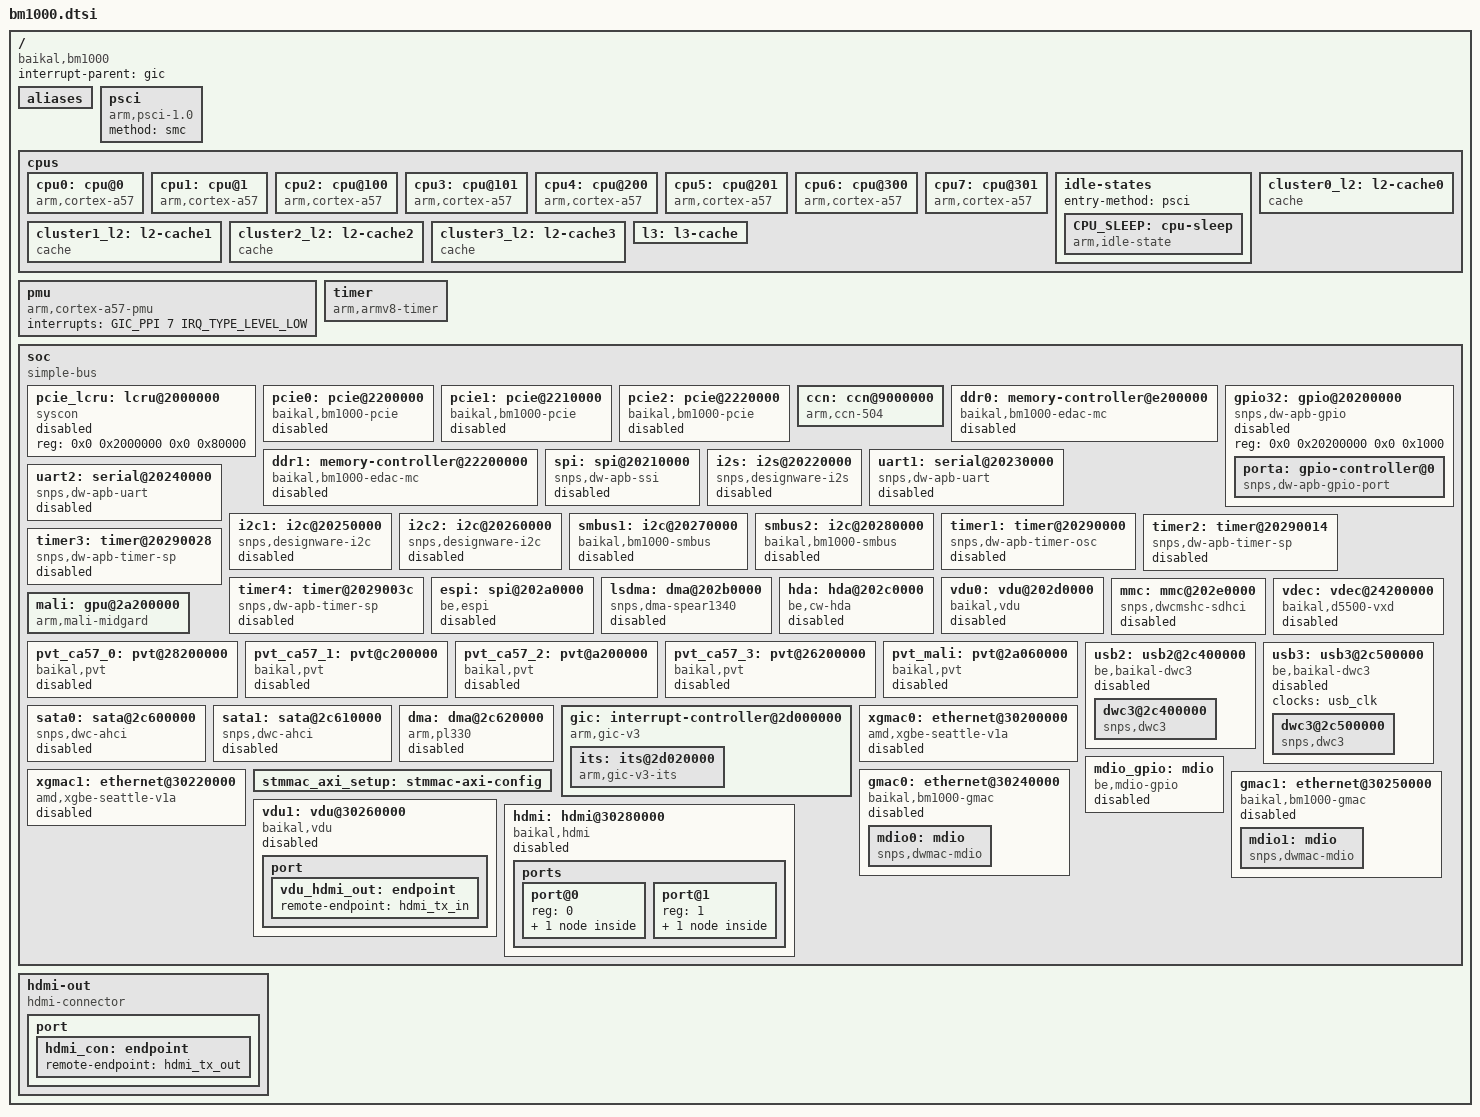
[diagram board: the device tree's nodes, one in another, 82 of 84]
// SPDX-License-Identifier: GPL-2.0
/*
 * Device tree include file for BE-M1000 SoC
 * Copyright (C) 2017-2021 Baikal Electronics, JSC
 */

#include "bm1000-clocks.dtsi"
#include <dt-bindings/gpio/gpio.h>
#include <dt-bindings/interrupt-controller/arm-gic.h>

/ {
	compatible = "baikal,bm1000";
	#address-cells = <2>;
	#size-cells = <2>;
	interrupt-parent = <&gic>;

	aliases {
		i2c1	= &i2c1;
		i2c2	= &i2c2;
		i2c3	= &smbus1;
		i2c4	= &smbus2;
		serial0	= &uart1;
		serial1	= &uart2;
	};

	psci {
		compatible = "arm,psci-1.0", "arm,psci-0.2";
		method = "smc";
	};

	cpus {
		#address-cells = <2>;
		#size-cells = <0>;

		/* Do not use 'cpu-map'. It leads to wrong topology. */

		cpu0: cpu@0 {
			device_type = "cpu";
			compatible = "arm,cortex-a57";
			reg = <0x0 0x0>;
			enable-method = "psci";
			i-cache-size = <0xc000>;
			i-cache-line-size = <64>;
			i-cache-sets = <256>;
			d-cache-size = <0x8000>;
			d-cache-line-size = <64>;
			d-cache-sets = <256>;
			next-level-cache = <&cluster0_l2>;
			clocks = <&cmu_cluster0>;
			clock-names = "baikal-ca57_cmu";
			operating-points-v2 = <&cluster0_opp>;
			cpu-idle-states = <&CPU_SLEEP>;
		};

		cpu1: cpu@1 {
			device_type = "cpu";
			compatible = "arm,cortex-a57";
			reg = <0x0 0x1>;
			enable-method = "psci";
			i-cache-size = <0xc000>;
			i-cache-line-size = <64>;
			i-cache-sets = <256>;
			d-cache-size = <0x8000>;
			d-cache-line-size = <64>;
			d-cache-sets = <256>;
			next-level-cache = <&cluster0_l2>;
			clocks = <&cmu_cluster0>;
			clock-names = "baikal-ca57_cmu";
			operating-points-v2 = <&cluster0_opp>;
			cpu-idle-states = <&CPU_SLEEP>;
		};

		cpu2: cpu@100 {
			device_type = "cpu";
			compatible = "arm,cortex-a57";
			reg = <0x0 0x100>;
			enable-method = "psci";
			i-cache-size = <0xc000>;
			i-cache-line-size = <64>;
			i-cache-sets = <256>;
			d-cache-size = <0x8000>;
			d-cache-line-size = <64>;
			d-cache-sets = <256>;
			next-level-cache = <&cluster1_l2>;
			clocks = <&cmu_cluster1>;
			clock-names = "baikal-ca57_cmu";
			operating-points-v2 = <&cluster1_opp>;
			cpu-idle-states = <&CPU_SLEEP>;
		};

		cpu3: cpu@101 {
			device_type = "cpu";
			compatible = "arm,cortex-a57";
			reg = <0x0 0x101>;
			enable-method = "psci";
			i-cache-size = <0xc000>;
			i-cache-line-size = <64>;
			i-cache-sets = <256>;
			d-cache-size = <0x8000>;
			d-cache-line-size = <64>;
			d-cache-sets = <256>;
			next-level-cache = <&cluster1_l2>;
			clocks = <&cmu_cluster1>;
			clock-names = "baikal-ca57_cmu";
			operating-points-v2 = <&cluster1_opp>;
			cpu-idle-states = <&CPU_SLEEP>;
		};

		cpu4: cpu@200 {
			device_type = "cpu";
			compatible = "arm,cortex-a57";
			reg = <0x0 0x200>;
			enable-method = "psci";
			i-cache-size = <0xc000>;
			i-cache-line-size = <64>;
			i-cache-sets = <256>;
			d-cache-size = <0x8000>;
			d-cache-line-size = <64>;
			d-cache-sets = <256>;
			next-level-cache = <&cluster2_l2>;
			clocks = <&cmu_cluster2>;
			clock-names = "baikal-ca57_cmu";
			operating-points-v2 = <&cluster2_opp>;
			cpu-idle-states = <&CPU_SLEEP>;
		};

		cpu5: cpu@201 {
			device_type = "cpu";
			compatible = "arm,cortex-a57";
			reg = <0x0 0x201>;
			enable-method = "psci";
			i-cache-size = <0xc000>;
			i-cache-line-size = <64>;
			i-cache-sets = <256>;
			d-cache-size = <0x8000>;
			d-cache-line-size = <64>;
			d-cache-sets = <256>;
			next-level-cache = <&cluster2_l2>;
			clocks = <&cmu_cluster2>;
			clock-names = "baikal-ca57_cmu";
			operating-points-v2 = <&cluster2_opp>;
			cpu-idle-states = <&CPU_SLEEP>;
		};

		cpu6: cpu@300 {
			device_type = "cpu";
			compatible = "arm,cortex-a57";
			reg = <0x0 0x300>;
			enable-method = "psci";
			i-cache-size = <0xc000>;
			i-cache-line-size = <64>;
			i-cache-sets = <256>;
			d-cache-size = <0x8000>;
			d-cache-line-size = <64>;
			d-cache-sets = <256>;
			next-level-cache = <&cluster3_l2>;
			clocks = <&cmu_cluster3>;
			clock-names = "baikal-ca57_cmu";
			operating-points-v2 = <&cluster3_opp>;
			cpu-idle-states = <&CPU_SLEEP>;
		};

		cpu7: cpu@301 {
			device_type = "cpu";
			compatible = "arm,cortex-a57";
			reg = <0x0 0x301>;
			enable-method = "psci";
			i-cache-size = <0xc000>;
			i-cache-line-size = <64>;
			i-cache-sets = <256>;
			d-cache-size = <0x8000>;
			d-cache-line-size = <64>;
			d-cache-sets = <256>;
			next-level-cache = <&cluster3_l2>;
			clocks = <&cmu_cluster3>;
			clock-names = "baikal-ca57_cmu";
			operating-points-v2 = <&cluster3_opp>;
			cpu-idle-states = <&CPU_SLEEP>;
		};

		idle-states {
			entry-method = "psci";

			CPU_SLEEP: cpu-sleep {
				compatible = "arm,idle-state";
				local-timer-stop;
				arm,psci-suspend-param = <0x0000001>;
				entry-latency-us = <300>;
				exit-latency-us = <1200>;
				min-residency-us = <2000>;
			};
		};

		cluster0_l2: l2-cache0 {
			compatible = "cache";
			cache-size = <0x100000>;
			cache-line-size = <64>;
			cache-sets = <1024>;
			cache-unified;
			cache-level = <2>;
			next-level-cache = <&l3>;
		};

		cluster1_l2: l2-cache1 {
			compatible = "cache";
			cache-size = <0x100000>;
			cache-line-size = <64>;
			cache-sets = <1024>;
			cache-unified;
			cache-level = <2>;
			next-level-cache = <&l3>;
		};

		cluster2_l2: l2-cache2 {
			compatible = "cache";
			cache-size = <0x100000>;
			cache-line-size = <64>;
			cache-sets = <1024>;
			cache-unified;
			cache-level = <2>;
			next-level-cache = <&l3>;
		};

		cluster3_l2: l2-cache3 {
			compatible = "cache";
			cache-size = <0x100000>;
			cache-line-size = <64>;
			cache-sets = <1024>;
			cache-unified;
			cache-level = <2>;
			next-level-cache = <&l3>;
		};

		l3: l3-cache {
			cache-size = <0x800000>;
			cache-unified;
			cache-level = <3>;
		};
	};

	pmu {
		compatible = "arm,cortex-a57-pmu";
		interrupts = <GIC_PPI 7 IRQ_TYPE_LEVEL_LOW>;
	};

	timer {
		compatible = "arm,armv8-timer";
		interrupts = <GIC_PPI 13 IRQ_TYPE_LEVEL_LOW>,
			     <GIC_PPI 14 IRQ_TYPE_LEVEL_LOW>,
			     <GIC_PPI 11 IRQ_TYPE_LEVEL_LOW>,
			     <GIC_PPI 10 IRQ_TYPE_LEVEL_LOW>;
	};

	soc {
		compatible = "simple-bus";
		#address-cells = <2>;
		#size-cells = <2>;
		ranges;

		pcie_lcru: lcru@2000000 {
			compatible = "syscon";
			reg = <0x0 0x2000000 0x0 0x80000>;
			status = "disabled";
		};

		pcie0: pcie@2200000 { /* PCIe x4 #0 */
			compatible = "baikal,bm1000-pcie", "baikal,pcie-m", "snps,dw-pcie";
			reg = <0x0 0x02200000 0x0 0x1000>,   /* RC config space */
			      <0x0 0x40100000 0x0 0x100000>; /* PCI config space */
			reg-names = "dbi", "config";
			interrupts = <GIC_SPI 426 IRQ_TYPE_LEVEL_HIGH>, /* AER */
				     <GIC_SPI 429 IRQ_TYPE_LEVEL_HIGH>; /* MSI */
			#interrupt-cells = <1>;
			baikal,pcie-lcru = <&pcie_lcru 0>;
			#address-cells = <3>;
			#size-cells = <2>;
			device_type = "pci";
			ranges = <0x81000000 0x0 0x00000000 0x0 0x40200000 0x0 0x100000>,   /* I/O */
				 <0x82000000 0x0 0x40000000 0x4 0x00000000 0x0 0x40000000>; /* 32b non-prefetchable memory */
			msi-parent = <&its 0x0>;
			msi-map = <0x0 &its 0x0 0x10000>;
			num-lanes = <4>;
			num-viewport = <4>;
			bus-range = <0x0 0xff>;
			status = "disabled";
		};

		pcie1: pcie@2210000 { /* PCIe x4 #1 */
			compatible = "baikal,bm1000-pcie", "baikal,pcie-m", "snps,dw-pcie";
			reg = <0x0 0x02210000 0x0 0x1000>,   /* RC config space */
			      <0x0 0x50100000 0x0 0x100000>; /* PCI config space */
			reg-names = "dbi", "config";
			interrupts = <GIC_SPI 402 IRQ_TYPE_LEVEL_HIGH>,	/* AER */
				     <GIC_SPI 405 IRQ_TYPE_LEVEL_HIGH>;	/* MSI */
			#interrupt-cells = <1>;
			baikal,pcie-lcru = <&pcie_lcru 1>;
			#address-cells = <3>;
			#size-cells = <2>;
			device_type = "pci";
			ranges = <0x81000000 0x0 0x00100000 0x0 0x50000000 0x0 0x100000>,   /* I/O */
				 <0x82000000 0x0 0x40000000 0x5 0x00000000 0x0 0x40000000>; /* 32b non-prefetchable memory */
			msi-parent = <&its 0x0>;
			msi-map = <0x0 &its 0x0 0x10000>;
			num-lanes = <4>;
			num-viewport = <4>;
			bus-range = <0x0 0xff>;
			status = "disabled";
		};

		pcie2: pcie@2220000 { /* PCIe x8 */
			compatible = "baikal,bm1000-pcie", "baikal,pcie-m", "snps,dw-pcie";
			reg = <0x0 0x02220000 0x0 0x1000>,   /* RC config space */
			      <0x0 0x60000000 0x0 0x100000>; /* PCI config space */
			reg-names = "dbi", "config";
			interrupts = <GIC_SPI 378 IRQ_TYPE_LEVEL_HIGH>, /* AER */
				     <GIC_SPI 381 IRQ_TYPE_LEVEL_HIGH>; /* MSI */
			#interrupt-cells = <1>;
			baikal,pcie-lcru = <&pcie_lcru 2>;
			#address-cells = <3>;
			#size-cells = <2>;
			device_type = "pci";
			ranges = <0x81000000 0x0 0x00200000 0x0 0x60100000 0x0 0x100000>,   /* I/O */
				 <0x82000000 0x0 0x80000000 0x6 0x00000000 0x0 0x80000000>; /* 32b non-prefetchable memory */
			msi-parent = <&its 0x0>;
			msi-map = <0x0 &its 0x0 0x10000>;
			num-lanes = <8>;
			num-viewport = <4>;
			bus-range = <0x0 0xff>;
			status = "disabled";
		};

		ccn: ccn@9000000 {
			compatible = "arm,ccn-504";
			reg = <0x0 0x9000000 0 0x1000000>;
			interrupts = <GIC_SPI 127 IRQ_TYPE_LEVEL_HIGH>;
		};

		ddr0: memory-controller@e200000 {
			compatible = "baikal,bm1000-edac-mc";
			reg = <0x0 0x0e200000 0x0 0x10000>;
			interrupts = <GIC_SPI 129 IRQ_TYPE_LEVEL_HIGH>, /* dfi_alert_err */
				     <GIC_SPI 130 IRQ_TYPE_LEVEL_HIGH>, /* ecc_corrected_err */
				     <GIC_SPI 131 IRQ_TYPE_LEVEL_HIGH>, /* ecc_uncorrected_err */
				     <GIC_SPI 132 IRQ_TYPE_LEVEL_HIGH>, /* sbr_done */
				     <GIC_SPI 133 IRQ_TYPE_LEVEL_HIGH>, /* ecc_corrected_err_fault */
				     <GIC_SPI 134 IRQ_TYPE_LEVEL_HIGH>; /* ecc_uncorrected_err_fault */
			clocks = <&soc_smc50mhz>;
			clock-names = "apb_pclk";
			status = "disabled";
		};

		ddr1: memory-controller@22200000 {
			compatible = "baikal,bm1000-edac-mc";
			reg = <0x0 0x22200000 0x0 0x10000>;
			interrupts = <GIC_SPI 139 IRQ_TYPE_LEVEL_HIGH>, /* dfi_alert_err */
				     <GIC_SPI 140 IRQ_TYPE_LEVEL_HIGH>, /* ecc_corrected_err */
				     <GIC_SPI 141 IRQ_TYPE_LEVEL_HIGH>, /* ecc_uncorrected_err */
				     <GIC_SPI 142 IRQ_TYPE_LEVEL_HIGH>, /* sbr_done */
				     <GIC_SPI 143 IRQ_TYPE_LEVEL_HIGH>, /* ecc_corrected_err_fault */
				     <GIC_SPI 144 IRQ_TYPE_LEVEL_HIGH>; /* ecc_uncorrected_err_fault */
			clocks = <&soc_smc50mhz>;
			clock-names = "apb_pclk";
			status = "disabled";
		};

		gpio32: gpio@20200000 {
			compatible = "snps,dw-apb-gpio";
			reg = <0x0 0x20200000 0x0 0x1000>;
			#address-cells = <1>;
			#size-cells = <0>;
			status = "disabled";

			porta: gpio-controller@0 {
				compatible = "snps,dw-apb-gpio-port";
				gpio-controller;
				#gpio-cells = <2>;
				snps,nr-gpios = <32>;
				reg = <0>;
				interrupt-controller;
				#interrupt-cells = <2>;
				interrupts = <GIC_SPI 99 IRQ_TYPE_LEVEL_HIGH>;
			};
		};

		spi: spi@20210000 {
			compatible = "snps,dw-apb-ssi";
			reg = <0x0 0x20210000 0x0 0x1000>;
			#address-cells = <1>;
			#size-cells = <0>;
			interrupts = <GIC_SPI 100 IRQ_TYPE_LEVEL_HIGH>;
			clocks = <&cmu0_avlsp 4>;
			clock-names = "soc_spiclk";
			status = "disabled";
		};

		i2s: i2s@20220000 {
			compatible = "snps,designware-i2s";
			reg = <0x0 0x20220000 0x0 0x10000>;
			interrupts = <GIC_SPI 104 IRQ_TYPE_LEVEL_HIGH>, /* rx_da */
				     <GIC_SPI 105 IRQ_TYPE_LEVEL_HIGH>, /* rx_or */
				     <GIC_SPI 106 IRQ_TYPE_LEVEL_HIGH>, /* tx_emp */
				     <GIC_SPI 107 IRQ_TYPE_LEVEL_HIGH>; /* tx_or */
			/*dmas = <&lsdma 0 1 0>,*/
			/*       <&lsdma 1 0 1>;*/
			/*dma-names = "tx", "rx";*/
			/*#sound-dai-cells = <0>;*/
			clocks = <&soc_tmp_clk>;
			clock-names = "i2sclk";
			status = "disabled";
		};

		uart1: serial@20230000 {
			compatible = "snps,dw-apb-uart";
			reg = <0x0 0x20230000 0x0 0x100>;
			interrupts = <GIC_SPI 101 IRQ_TYPE_LEVEL_HIGH>;
			reg-shift = <2>;
			reg-io-width = <4>;
			clocks = <&cmu0_avlsp 1>, <&apb_clk>;
			clock-names = "soc_uartclk", "apb_pclk";
			status = "disabled";
		};

		uart2: serial@20240000 {
			compatible = "snps,dw-apb-uart";
			reg = <0x0 0x20240000 0x0 0x100>;
			interrupts = <GIC_SPI 102 IRQ_TYPE_LEVEL_HIGH>;
			reg-shift = <2>;
			reg-io-width = <4>;
			clocks = <&cmu0_avlsp 2>, <&apb_clk>;
			clock-names = "soc_uartclk", "apb_pclk";
			status = "disabled";
		};

		i2c1: i2c@20250000 {
			compatible = "snps,designware-i2c";
			#address-cells = <1>;
			#size-cells = <0>;
			reg = <0x0 0x20250000 0x0 0x1000>;
			interrupts = <GIC_SPI 108 IRQ_TYPE_LEVEL_HIGH>;
			i2c-sda-hold-time-ns = <500>;
			clock-frequency = <400000>;
			clocks = <&i2c_clk>;
			clock-names = "soc_i2cclk";
			status = "disabled";
		};

		i2c2: i2c@20260000 {
			compatible = "snps,designware-i2c";
			#address-cells = <1>;
			#size-cells = <0>;
			reg = <0x0 0x20260000 0x0 0x1000>;
			interrupts = <GIC_SPI 109 IRQ_TYPE_LEVEL_HIGH>;
			i2c-sda-hold-time-ns = <500>;
			clock-frequency = <400000>;
			clocks = <&i2c_clk>;
			clock-names = "soc_i2cclk";
			status = "disabled";
		};

		smbus1: i2c@20270000 {
			compatible = "baikal,bm1000-smbus", "be,smbus";
			#address-cells = <1>;
			#size-cells = <0>;
			reg = <0x0 0x20270000 0x0 0x1000>;
			interrupts = <GIC_SPI 110 IRQ_TYPE_LEVEL_HIGH>;
			clock-frequency = <100000>;
			clocks = <&smbus_clk>;
			clock-names = "soc_smbusclk";
			status = "disabled";
		};

		smbus2: i2c@20280000 {
			compatible = "baikal,bm1000-smbus", "be,smbus";
			#address-cells = <1>;
			#size-cells = <0>;
			reg = <0x0 0x20280000 0x0 0x1000>;
			interrupts = <GIC_SPI 111 IRQ_TYPE_LEVEL_HIGH>;
			clock-frequency = <100000>;
			clocks = <&smbus_clk>;
			clock-names = "soc_smbusclk";
			status = "disabled";
		};

		timer1: timer@20290000 {
			compatible = "snps,dw-apb-timer-osc";
			reg = <0x0 0x20290000 0x0 0x14>;
			interrupts = <GIC_SPI 95 IRQ_TYPE_LEVEL_HIGH>;
			clock-frequency = <50000000>;
			clocks = <&timer1_clk>;
			clock-names = "soc_timer1clk";
			status = "disabled";
		};

		timer2: timer@20290014 {
			compatible = "snps,dw-apb-timer-sp";
			reg = <0x0 0x20290014 0x0 0x14>;
			interrupts = <GIC_SPI 96 IRQ_TYPE_LEVEL_HIGH>;
			clock-frequency = <50000000>;
			clocks = <&timer2_clk>;
			clock-names = "soc_timer2clk";
			status = "disabled";
		};

		timer3: timer@20290028 {
			compatible = "snps,dw-apb-timer-sp";
			reg = <0x0 0x20290028 0x0 0x14>;
			interrupts = <GIC_SPI 97 IRQ_TYPE_LEVEL_HIGH>;
			clock-frequency = <50000000>;
			clocks = <&timer3_clk>;
			clock-names = "soc_timer3clk";
			status = "disabled";
		};

		timer4: timer@2029003c {
			compatible = "snps,dw-apb-timer-sp";
			reg = <0x0 0x2029003c 0x0 0x14>;
			interrupts = <GIC_SPI 98 IRQ_TYPE_LEVEL_HIGH>;
			clock-frequency = <50000000>;
			clocks = <&timer4_clk>;
			clock-names = "soc_timer4clk";
			status = "disabled";
		};

		espi: spi@202a0000 {
			compatible = "be,espi";
			reg = <0x0 0x202a0000 0x0 0x1000>;
			#address-cells = <1>;
			#size-cells = <0>;
			interrupts = <GIC_SPI 103 IRQ_TYPE_LEVEL_HIGH>;
			clocks = <&cmu0_avlsp 5>;
			clock-names = "soc_espiclk";
			status = "disabled";
			/*
			 * Block Configuration:
			 * - master/slave
			 * - 32-bit APB slave
			 * - tx-fifo = rx-fifo = 256 byte
			 * - 4 SPI IO channels
			 * - 8 slave select IO channels
			 * - DMA - missing
			 * - M-flash controller - missing
			 */
		};

		lsdma: dma@202b0000 {
			compatible = "snps,dma-spear1340";
			reg = <0x0 0x202b0000 0x0 0x10000>;
			interrupts = <GIC_SPI 9 IRQ_TYPE_LEVEL_HIGH>,
				     <GIC_SPI 10 IRQ_TYPE_LEVEL_HIGH>,
				     <GIC_SPI 11 IRQ_TYPE_LEVEL_HIGH>,
				     <GIC_SPI 12 IRQ_TYPE_LEVEL_HIGH>,
				     <GIC_SPI 13 IRQ_TYPE_LEVEL_HIGH>,
				     <GIC_SPI 14 IRQ_TYPE_LEVEL_HIGH>,
				     <GIC_SPI 15 IRQ_TYPE_LEVEL_HIGH>,
				     <GIC_SPI 16 IRQ_TYPE_LEVEL_HIGH>,
				     <GIC_SPI 17 IRQ_TYPE_LEVEL_HIGH>,
				     <GIC_SPI 18 IRQ_TYPE_LEVEL_HIGH>,
				     <GIC_SPI 19 IRQ_TYPE_LEVEL_HIGH>,
				     <GIC_SPI 20 IRQ_TYPE_LEVEL_HIGH>,
				     <GIC_SPI 21 IRQ_TYPE_LEVEL_HIGH>,
				     <GIC_SPI 22 IRQ_TYPE_LEVEL_HIGH>,
				     <GIC_SPI 23 IRQ_TYPE_LEVEL_HIGH>,
				     <GIC_SPI 24 IRQ_TYPE_LEVEL_HIGH>,
				     <GIC_SPI 25 IRQ_TYPE_LEVEL_HIGH>,
				     <GIC_SPI 26 IRQ_TYPE_LEVEL_HIGH>,
				     <GIC_SPI 27 IRQ_TYPE_LEVEL_HIGH>,
				     <GIC_SPI 28 IRQ_TYPE_LEVEL_HIGH>,
				     <GIC_SPI 29 IRQ_TYPE_LEVEL_HIGH>,
				     <GIC_SPI 30 IRQ_TYPE_LEVEL_HIGH>,
				     <GIC_SPI 31 IRQ_TYPE_LEVEL_HIGH>,
				     <GIC_SPI 32 IRQ_TYPE_LEVEL_HIGH>,
				     <GIC_SPI 33 IRQ_TYPE_LEVEL_HIGH>,
				     <GIC_SPI 34 IRQ_TYPE_LEVEL_HIGH>,
				     <GIC_SPI 35 IRQ_TYPE_LEVEL_HIGH>,
				     <GIC_SPI 36 IRQ_TYPE_LEVEL_HIGH>,
				     <GIC_SPI 37 IRQ_TYPE_LEVEL_HIGH>,
				     <GIC_SPI 38 IRQ_TYPE_LEVEL_HIGH>,
				     <GIC_SPI 39 IRQ_TYPE_LEVEL_HIGH>,
				     <GIC_SPI 40 IRQ_TYPE_LEVEL_HIGH>,
				     <GIC_SPI 41 IRQ_TYPE_LEVEL_HIGH>,
				     <GIC_SPI 42 IRQ_TYPE_LEVEL_HIGH>,
				     <GIC_SPI 43 IRQ_TYPE_LEVEL_HIGH>,
				     <GIC_SPI 44 IRQ_TYPE_LEVEL_HIGH>,
				     <GIC_SPI 45 IRQ_TYPE_LEVEL_HIGH>,
				     <GIC_SPI 46 IRQ_TYPE_LEVEL_HIGH>,
				     <GIC_SPI 47 IRQ_TYPE_LEVEL_HIGH>,
				     <GIC_SPI 48 IRQ_TYPE_LEVEL_HIGH>;
			dma-channels = <8>;
			dma-requests = <16>;
			dma-masters = <2>;
			#dma-cells = <3>;
			chan_allocation_order = <0>;
			chan_priority = <0>;
			block_size = <0xff>;
			data-width = <4 16>;
			clocks = <&cmu0_avlsp 12>;
			clock-names = "dmac";
			snps,dma-protection-control = <0>;
			status = "disabled";
		};

		hda: hda@202c0000 {
			compatible = "be,cw-hda";
			reg = <0x0 0x202c0000 0x0 0x1000>;
			interrupts = <GIC_SPI 54 IRQ_TYPE_LEVEL_HIGH>;
			clocks = <&cmu0_avlsp 15>, <&cmu0_avlsp 16>;
			clock-names = "hda_sys_clk", "hda_clk48";
			status = "disabled";
			force-polling-mode;
			broken-response-irq;
			increment-codec-address;
			cyclic-codec-probe;
		};

		vdu0: vdu@202d0000 {
			compatible = "baikal,vdu";
			reg = <0x0 0x202d0000 0x0 0x1000>;
			interrupts = <GIC_SPI 112 IRQ_TYPE_LEVEL_HIGH>, /* VDU INTR */
				     <GIC_SPI 113 IRQ_TYPE_LEVEL_HIGH>; /* VDU INTR_CDD */
			clocks = <&cmu1_avlsp_div7>;
			clock-names = "pclk";
			lvds-out;
			status = "disabled";
		};

		mmc: mmc@202e0000 {
			compatible = "snps,dwcmshc-sdhci";
			reg = <0x0 0x202e0000 0x0 0x10000>;
			interrupts = <GIC_SPI 51 IRQ_TYPE_LEVEL_HIGH>,
				     <GIC_SPI 52 IRQ_TYPE_LEVEL_HIGH>;
			clock-names = "bus", "core";
			clocks = <&cmu0_avlsp 18>, <&cmu0_avlsp 19>;
			status = "disabled";
		};

		vdec: vdec@24200000 {
			compatible = "baikal,d5500-vxd";
			reg = <0x0 0x24200000 0x0 0x10000>;
			interrupts = <GIC_SPI 497 IRQ_TYPE_LEVEL_HIGH>;
			status = "disabled";
		};

		mali: gpu@2a200000 {
			compatible = "arm,mali-midgard", "arm,mali-t628";
			#cooling-cells = <2>; /* min followed by max */
			reg = <0x0 0x2a200000 0x0 0x4000>;
			interrupts = <GIC_SPI 175 IRQ_TYPE_LEVEL_HIGH>,
				     <GIC_SPI 176 IRQ_TYPE_LEVEL_HIGH>,
				     <GIC_SPI 174 IRQ_TYPE_LEVEL_HIGH>;
			interrupt-names = "job", "mmu", "gpu";
			clocks = <&cmu_mali>;
			clock-names = "gpuclk";
			operating-points-v2 = <&gpu_opp_table>;
			system-coherency = <0>;
		};

		pvt_ca57_0: pvt@28200000 {
			compatible = "baikal,pvt";
			reg = <0x0 0x28200000 0x0 0x10000>;
			pvt_id = <0>;
			interrupts = <GIC_SPI 119 IRQ_TYPE_LEVEL_HIGH>;
			status = "disabled";
		};

		pvt_ca57_1: pvt@c200000 {
			compatible = "baikal,pvt";
			reg = <0x0 0xc200000 0x0 0x10000>;
			pvt_id = <1>;
			interrupts = <GIC_SPI 121 IRQ_TYPE_LEVEL_HIGH>;
			status = "disabled";
		};

		pvt_ca57_2: pvt@a200000 {
			compatible = "baikal,pvt";
			reg = <0x0 0xa200000 0x0 0x10000>;
			pvt_id = <2>;
			interrupts = <GIC_SPI 123 IRQ_TYPE_LEVEL_HIGH>;
			status = "disabled";
		};

		pvt_ca57_3: pvt@26200000 {
			compatible = "baikal,pvt";
			reg = <0x0 0x26200000 0x0 0x10000>;
			pvt_id = <3>;
			interrupts = <GIC_SPI 125 IRQ_TYPE_LEVEL_HIGH>;
			status = "disabled";
		};

		pvt_mali: pvt@2a060000 {
			compatible = "baikal,pvt";
			reg = <0x0 0x2a060000 0x0 0x10000>;
			pvt_id = <4>;
			interrupts = <GIC_SPI 221 IRQ_TYPE_LEVEL_HIGH>;
			status = "disabled";
		};

		usb2: usb2@2c400000 {
			compatible = "be,baikal-dwc3";
			status = "disabled";
			#address-cells = <2>;
			#size-cells = <2>;
			ranges;
			clocks = <&usb_clk>;
			clock-names = "usb";
			dma-coherent;

			dwc3@2c400000 {
				compatible = "snps,dwc3", "synopsys,dwc3", "generic-xhci";
				reg = <0x0 0x2c400000 0x0 0x100000>;
				interrupts = <GIC_SPI 235 IRQ_TYPE_LEVEL_HIGH>,
					     <GIC_SPI 236 IRQ_TYPE_LEVEL_HIGH>,
					     <GIC_SPI 245 IRQ_TYPE_LEVEL_HIGH>;
				dr_mode = "host";
				dma-coherent;
				maximum-speed = "high-speed";
			};
		};

		usb3: usb3@2c500000 {
			compatible = "be,baikal-dwc3";
			status = "disabled";
			#address-cells = <2>;
			#size-cells = <2>;
			ranges;
			clocks = <&usb_clk>;
			clock-names = "usb";

			dwc3@2c500000 {
				compatible = "snps,dwc3", "synopsys,dwc3", "generic-xhci";
				reg = <0x0 0x2c500000 0x0 0x100000>;
				interrupts = <GIC_SPI 237 IRQ_TYPE_LEVEL_HIGH>,
					     <GIC_SPI 238 IRQ_TYPE_LEVEL_HIGH>,
					     <GIC_SPI 239 IRQ_TYPE_LEVEL_HIGH>,
					     <GIC_SPI 240 IRQ_TYPE_LEVEL_HIGH>,
					     <GIC_SPI 241 IRQ_TYPE_LEVEL_HIGH>,
					     <GIC_SPI 242 IRQ_TYPE_LEVEL_HIGH>,
					     <GIC_SPI 243 IRQ_TYPE_LEVEL_HIGH>,
					     <GIC_SPI 244 IRQ_TYPE_LEVEL_HIGH>,
					     <GIC_SPI 246 IRQ_TYPE_LEVEL_HIGH>;
				dr_mode = "host";
				dma-coherent;
			};
		};

		sata0: sata@2c600000 {
			compatible = "snps,dwc-ahci", "generic-ahci";
			reg = <0x0 0x2c600000 0 0x10000>;
			interrupts = <GIC_SPI 233 IRQ_TYPE_LEVEL_HIGH>;
			ports-implemented = <1>;
			dma-coherent;
			clocks = <&soc_faxiclk>;
			clock-names = "sataclk";
			status = "disabled";
		};

		sata1: sata@2c610000 {
			compatible = "snps,dwc-ahci", "generic-ahci";
			reg = <0x0 0x2c610000 0 0x10000>;
			interrupts = <GIC_SPI 234 IRQ_TYPE_LEVEL_HIGH>;
			ports-implemented = <1>;
			dma-coherent;
			clocks = <&soc_faxiclk>;
			clock-names = "sataclk";
			status = "disabled";
		};

		dma: dma@2c620000 {
			compatible = "arm,pl330", "arm,primecell";
			reg = <0x0 0x2c620000 0 0x1000>;
			#dma-cells = <1>;
			#dma-channels = <8>;
			#dma-requests = <32>;
			interrupts = <GIC_SPI 223 IRQ_TYPE_LEVEL_HIGH>,
				     <GIC_SPI 224 IRQ_TYPE_LEVEL_HIGH>,
				     <GIC_SPI 225 IRQ_TYPE_LEVEL_HIGH>,
				     <GIC_SPI 226 IRQ_TYPE_LEVEL_HIGH>,
				     <GIC_SPI 227 IRQ_TYPE_LEVEL_HIGH>,
				     <GIC_SPI 228 IRQ_TYPE_LEVEL_HIGH>,
				     <GIC_SPI 229 IRQ_TYPE_LEVEL_HIGH>,
				     <GIC_SPI 230 IRQ_TYPE_LEVEL_HIGH>,
				     <GIC_SPI 231 IRQ_TYPE_LEVEL_HIGH>;
			clocks = <&soc_faxiclk>;
			clock-names = "apb_pclk";
			status = "disabled";
		};

		gic: interrupt-controller@2d000000 {
			compatible = "arm,gic-v3";
			#interrupt-cells = <3>;
			#address-cells = <2>;
			#size-cells = <2>;
			ranges;
			interrupt-controller;
			reg = <0x0 0x2d000000 0x0 0x10000>,  /* GICD */
			      <0x0 0x2d100000 0x0 0x200000>, /* GICR */
			      <0x0 0x10200000 0x0 0x2000>,   /* GICC */
			      <0x0 0x10210000 0x0 0x1000>,   /* GICH */
			      <0x0 0x10220000 0x0 0x2000>;   /* GICV */
			interrupts = <GIC_PPI 9 IRQ_TYPE_LEVEL_HIGH>;

			its: its@2d020000 {
				compatible = "arm,gic-v3-its";
				msi-controller;
				#msi-cells = <1>;
				reg = <0x0 0x2d020000 0x0 0x20000>; /* GITS */
			};
		};

		xgmac0: ethernet@30200000 {
			compatible = "amd,xgbe-seattle-v1a";
			reg = <0x0 0x30200000 0x0 0x10000>,
			      <0x0 0x30210000 0x0 0x10000>;
			interrupts = <GIC_SPI 293 IRQ_TYPE_LEVEL_HIGH>,
				     <GIC_SPI 294 IRQ_TYPE_LEVEL_HIGH>,
				     <GIC_SPI 295 IRQ_TYPE_LEVEL_HIGH>,
				     <GIC_SPI 296 IRQ_TYPE_LEVEL_HIGH>,
				     <GIC_SPI 297 IRQ_TYPE_LEVEL_HIGH>,
				     <GIC_SPI 298 IRQ_TYPE_LEVEL_HIGH>,
				     <GIC_SPI 299 IRQ_TYPE_LEVEL_HIGH>,
				     <GIC_SPI 300 IRQ_TYPE_LEVEL_HIGH>,
				     <GIC_SPI 301 IRQ_TYPE_LEVEL_HIGH>,
				     <GIC_SPI 302 IRQ_TYPE_LEVEL_HIGH>,
				     <GIC_SPI 303 IRQ_TYPE_LEVEL_HIGH>,
				     <GIC_SPI 304 IRQ_TYPE_LEVEL_HIGH>,
				     <GIC_SPI 305 IRQ_TYPE_LEVEL_HIGH>,
				     <GIC_SPI 306 IRQ_TYPE_LEVEL_HIGH>,
				     <GIC_SPI 307 IRQ_TYPE_LEVEL_HIGH>,
				     <GIC_SPI 308 IRQ_TYPE_LEVEL_HIGH>,
				     <GIC_SPI 309 IRQ_TYPE_LEVEL_HIGH>;
			fsl,num-rx-queues=<3>;
			clocks = <&soc_xgbeclk>, <&soc_xgbeclk>, <&soc_xgbeclk>;
			clock-names = "dma_clk", "ptp_clk", "xgbe_clk";
			phy-mode = "xgmii";
			mac-address = [ 00 20 13 ba 1c a1 ];
			local-mac-address = [ 00 20 13 ba 1c a1 ];
			be,pcs-mode = "KX4";
			status = "disabled";
			amd,per-channel-interrupt;
			amd,speed-set = <0>;
			#stream-id-cells = <16>;
		};

		xgmac1: ethernet@30220000 {
			compatible = "amd,xgbe-seattle-v1a";
			reg = <0x0 0x30220000 0x0 0x10000>,
			      <0x0 0x30230000 0x0 0x10000>;
			interrupts = <GIC_SPI 310 IRQ_TYPE_LEVEL_HIGH>,
				     <GIC_SPI 311 IRQ_TYPE_LEVEL_HIGH>,
				     <GIC_SPI 312 IRQ_TYPE_LEVEL_HIGH>,
				     <GIC_SPI 313 IRQ_TYPE_LEVEL_HIGH>,
				     <GIC_SPI 314 IRQ_TYPE_LEVEL_HIGH>,
				     <GIC_SPI 315 IRQ_TYPE_LEVEL_HIGH>,
				     <GIC_SPI 316 IRQ_TYPE_LEVEL_HIGH>,
				     <GIC_SPI 317 IRQ_TYPE_LEVEL_HIGH>,
				     <GIC_SPI 318 IRQ_TYPE_LEVEL_HIGH>,
				     <GIC_SPI 319 IRQ_TYPE_LEVEL_HIGH>,
				     <GIC_SPI 320 IRQ_TYPE_LEVEL_HIGH>,
				     <GIC_SPI 321 IRQ_TYPE_LEVEL_HIGH>,
				     <GIC_SPI 322 IRQ_TYPE_LEVEL_HIGH>,
				     <GIC_SPI 323 IRQ_TYPE_LEVEL_HIGH>,
				     <GIC_SPI 324 IRQ_TYPE_LEVEL_HIGH>,
				     <GIC_SPI 325 IRQ_TYPE_LEVEL_HIGH>,
				     <GIC_SPI 326 IRQ_TYPE_LEVEL_HIGH>;
			fsl,num-rx-queues=<3>;
			clocks = <&soc_xgbeclk>, <&soc_xgbeclk>, <&soc_xgbeclk>;
			clock-names = "dma_clk", "ptp_clk", "xgbe_clk";
			phy-mode = "xgmii";
			mac-address = [ 00 20 13 ba 1c a2 ];
			local-mac-address = [ 00 20 13 ba 1c a2 ];
			be,pcs-mode = "KX4";
			status = "disabled";
			amd,per-channel-interrupt;
			amd,speed-set = <0>;
			#stream-id-cells = <16>;
		};

		mdio_gpio: mdio { /* internal MDIO */
			compatible = "be,mdio-gpio";
			#address-cells = <1>;
			#size-cells = <0>;
			mdc-pin = <&porta 30 GPIO_ACTIVE_HIGH>;
			mdio-pin = <&porta 29 GPIO_ACTIVE_HIGH>;
			clocks = <&gpio_clk>;
			clock-names = "gpioclk";
			status = "disabled";
		};

		stmmac_axi_setup: stmmac-axi-config {
			snps,wr_osr_lmt = <0x0>;
			snps,rd_osr_lmt = <0x0>;
			snps,blen = <0 0 0 0 0 0 4>;
		};

		gmac0: ethernet@30240000 {
			compatible = "baikal,bm1000-gmac", "be,dwmac";
			reg = <0x0 0x30240000 0x0 0x10000>;
			interrupts = <GIC_SPI 291 IRQ_TYPE_LEVEL_HIGH>;
			interrupt-names = "macirq";
			max-speed = <1000>;
			clocks = <&soc_ethclk>, <&cmu0_xgbe 10>;
			clock-names = "stmmaceth", "tx2_clk";
			mac-address = [ 00 00 00 00 00 00 ];
			local-mac-address = [ 00 00 00 00 00 00 ];
			snps,axi-config = <&stmmac_axi_setup>;
			snps,fixed-burst;
			snps,no-pbl-x8;
			snps,txpbl = <4>;
			snps,rxpbl = <4>;
			snps,reset-delays-us = <0 10200 1000>;
			status = "disabled";
			dma-coherent;

			mdio0: mdio {
				compatible = "snps,dwmac-mdio";
				#address-cells = <1>;
				#size-cells = <0>;
			};
		};

		gmac1: ethernet@30250000 {
			compatible = "baikal,bm1000-gmac", "be,dwmac";
			reg = <0x0 0x30250000 0x0 0x10000>;
			interrupts = <GIC_SPI 292 IRQ_TYPE_LEVEL_HIGH>;
			interrupt-names = "macirq";
			max-speed = <1000>;
			clocks = <&soc_ethclk>, <&cmu0_xgbe 13>;
			clock-names = "stmmaceth", "tx2_clk";
			mac-address = [ 00 00 00 00 00 00 ];
			local-mac-address = [ 00 00 00 00 00 00 ];
			snps,axi-config = <&stmmac_axi_setup>;
			snps,fixed-burst;
			snps,no-pbl-x8;
			snps,txpbl = <4>;
			snps,rxpbl = <4>;
			snps,reset-delays-us = <0 10200 1000>;
			status = "disabled";
			dma-coherent;

			mdio1: mdio {
				compatible = "snps,dwmac-mdio";
				#address-cells = <1>;
				#size-cells = <0>;
			};
		};

		vdu1: vdu@30260000 {
			compatible = "baikal,vdu";
			reg = <0x0 0x30260000 0x0 0x1000>;
			interrupts = <GIC_SPI 329 IRQ_TYPE_LEVEL_HIGH>, /* VDU INTR */
				     <GIC_SPI 330 IRQ_TYPE_LEVEL_HIGH>; /* VDU INTR_CDD */
			clocks = <&cmu1_xgbe 0>;
			clock-names = "pclk";
			status = "disabled";

			port {
				vdu_hdmi_out: endpoint {
					remote-endpoint = <&hdmi_tx_in>;
				};
			};
		};

		hdmi: hdmi@30280000 {
			compatible = "baikal,hdmi";
			reg = <0x0 0x30280000 0x0 0x20000>;
			reg-io-width = <4>;
			interrupts = <GIC_SPI 331 IRQ_TYPE_LEVEL_HIGH>;
			clocks = <&cmu0_xgbe 0>, <&cmu0_xgbe 17>;
			clock-names = "iahb", "isfr";
			status = "disabled";

			ports {
				#address-cells = <1>;
				#size-cells = <0>;
				port@0 {
					reg = <0>;
					hdmi_tx_in: endpoint {
						remote-endpoint = <&vdu_hdmi_out>;
					};
				};
				port@1 {
					reg = <1>;
					hdmi_tx_out: endpoint {
						remote-endpoint = <&hdmi_con>;
					};
				};
			};
		};
	};

	hdmi-out {
		compatible = "hdmi-connector";
		label = "HDMI0 OUT";
		type = "a";

		port {
			hdmi_con: endpoint {
				remote-endpoint = <&hdmi_tx_out>;
			};
		};
	};
};
